# DSS_EDP0_COMMON_0_V2A_CORE_VP_REGS_APB register map
Vendor: Texas Instruments
Registers are 32-bit, access not given, reset 0x0 unless marked. A register's access mark holds for its fields unless they carry their own. Offsets are as the file gives them; [hi:lo] are bit positions; lines under a group give offsets from that group; {n}, {i} and the like mark numbered series; 'fields as' and 'values as' point back to an identical list.

## DSS_EDP0_COMMON_0_V2A_CORE_VP_REGS_APB (part 3 of 3)
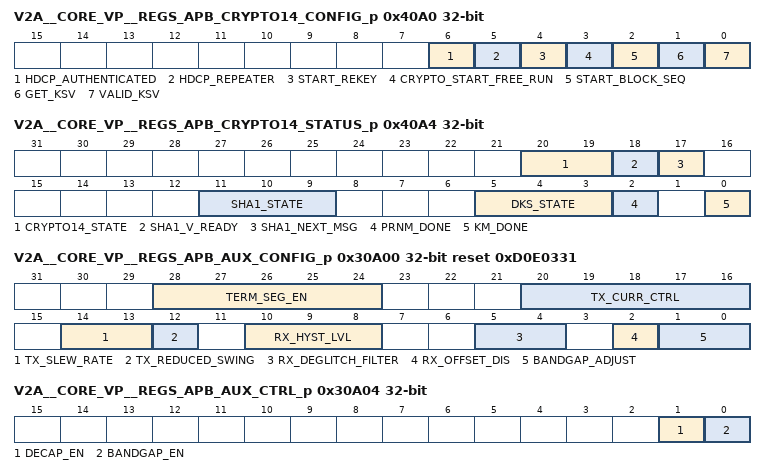
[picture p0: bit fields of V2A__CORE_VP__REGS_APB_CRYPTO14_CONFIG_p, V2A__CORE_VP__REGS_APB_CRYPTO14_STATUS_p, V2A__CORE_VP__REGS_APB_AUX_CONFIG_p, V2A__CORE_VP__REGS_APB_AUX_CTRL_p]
0x40A0 V2A__CORE_VP__REGS_APB_CRYPTO14_CONFIG_p
  [6] HDCP_AUTHENTICATED rw — Authenticated finished.
  [5] HDCP_REPEATER rw — Repeater bit : 0: for the receiver, 1: for the repeater
  [4] START_REKEY rw — Crypto 1.4 command to start hdcpRekeyCipher
  [3] CRYPTO_START_FREE_RUN rw — Crypto 1.4 command to start free running enable for operation hdcpRngCipher
  [2] START_BLOCK_SEQ rw — Crypto 1.4 command to start LFSR calculation
  [1] GET_KSV rw — Read it's own KSV enable bit.'0' reading not allowed'1' start reading.
  [0] VALID_KSV rw — Enable for Km calculation. When high, start calculating Km. Indicates a good moment for ri_out sampling.
0x40A4 V2A__CORE_VP__REGS_APB_CRYPTO14_STATUS_p
  [20:19] CRYPTO14_STATE ro — Crypto operation SM state: Possible values: 00- HDCP_RNG_CIPHER 01 - HDCP_BLOCK_CIPHER 10 - HDCP_STREAM_CIPHER 11 - HDCP_REKEY_CIPHER
  [18] SHA1_V_READY ro — Indication that V value from SHA-1 CRYPTO14_SHA1_V_VALUE_4 is ready.
  [17] SHA1_NEXT_MSG ro — Request for the next message block. When set high, CRYPTO14_SHA1_MSG_DATA_0-15 registers shall be written.
  [11:9] SHA1_STATE ro — Current state for Crypto 1.4 SHA-1 FSM. Used for debug purpose. Possible values: 000 - IDLE 001 - PREPARE 010 - CALCULATE 011 - RESULT 100 - BLOCK_WAIT
  [5:3] DKS_STATE ro — Crypto 1.4 DKS current state. Used for debug purpose. Possible values: 000 - HDCP_IDLE_KSV 010 - HDCP_IDLE 100 - HDCP_PRECALC 101 - HDCP_POSTCALC 110 - HDCP_CALC 111 - HDCP_READY
  [2] PRNM_DONE ro — LFSR and block output finished calculation.
  [0] KM_DONE ro — Done reading/calculating Km. Used as interrupt event.
0x40A8 V2A__CORE_VP__REGS_APB_CRYPTO14_PRNM_OUT_p
  [23:0] PRNM_OUT ro — 24-bit pseudo-random data.
0x40AC V2A__CORE_VP__REGS_APB_CRYPTO14_KM_0_p ro
  [31:0] CRYPTO14_KM_0 — Holds the first word of the Km value.
0x40B0 V2A__CORE_VP__REGS_APB_CRYPTO14_KM_1_p
  [23:0] CRYPTO14_KM_1 ro — Holds the most significant 3 bytes of the Km value.
0x40B4 V2A__CORE_VP__REGS_APB_CRYPTO14_AN_0_p rw
  [31:0] CRYPTO14_AN_0 — Holds the first 4 bytes of the An value.
0x40B8 V2A__CORE_VP__REGS_APB_CRYPTO14_AN_1_p rw
  [31:0] CRYPTO14_AN_1 — Holds the most significant 4 bytes of the An value.
0x40BC V2A__CORE_VP__REGS_APB_CRYPTO14_YOUR_KSV_0_p rw
  [31:0] CRYPTO14_YOUR_KSV_0 — Holds the first 32 bits of the KSV from the other HDCP device.
0x40C0 V2A__CORE_VP__REGS_APB_CRYPTO14_YOUR_KSV_1_p
  [7:0] CRYPTO14_YOUR_KSV_1 rw — Holds the last byte of the KSV from other HDCP device
0x40C4 V2A__CORE_VP__REGS_APB_CRYPTO14_MI_0_p ro
  [31:0] CRYPTO14_MI_0 — Mi value first 32 bits
0x40C8 V2A__CORE_VP__REGS_APB_CRYPTO14_MI_1_p ro
  [31:0] CRYPTO14_MI_1 — Mi value second 32 bits
0x40CC V2A__CORE_VP__REGS_APB_CRYPTO14_TI_0_p
  [15:0] CRYPTO14_TI_0 ro — Ti value
0x40D0 V2A__CORE_VP__REGS_APB_CRYPTO14_KI_0_p ro
  [31:0] CRYPTO14_KI_0 — Holds the first 32 bits of the Ki frame key from this HDCP device.
0x40D4 V2A__CORE_VP__REGS_APB_CRYPTO14_KI_1_p
  [23:0] CRYPTO14_KI_1 ro — Holds the last 3 bytes of the Ki frame key from this HDCP device.
0x40D8 V2A__CORE_VP__REGS_APB_CRYPTO14_BLOCKS_NUM_p rw
  [31:0] BLOCKS_NUM — Number of iterations for SHA-1 calculation.
0x40DC V2A__CORE_VP__REGS_APB_CRYPTO14_KEY_MEM_DATA_0_p rw
  [31:0] KEY_MEM_DATA_0 — Output data from keys RAM. Input for DKS block. First 32 bits.
0x40E0 V2A__CORE_VP__REGS_APB_CRYPTO14_KEY_MEM_DATA_1_p
  [23:0] KEY_MEM_DATA_1 rw — Output data from keys RAM. Input for DKS block. Last 3 bytes.
0x40E4 V2A__CORE_VP__REGS_APB_CRYPTO14_SHA1_MSG_DATA_p rw
  [31:0] SHA1_MSG_DATA — 32-bit word for SHA-1 message. Input for SHA-1 block.
0x40E8 V2A__CORE_VP__REGS_APB_CRYPTO14_SHA1_V_VALUE_0_p ro reset 0x67452301
  [31:0] V_VALUE_0 — First 32-bit word for SHA-1 calculation value. Output from SHA-1 block.
0x40EC V2A__CORE_VP__REGS_APB_CRYPTO14_SHA1_V_VALUE_1_p ro reset 0xEFCDAB89
  [31:0] V_VALUE_1 — Second 32-bit word for SHA-1 calculation value. Output from SHA-1 block.
0x40F0 V2A__CORE_VP__REGS_APB_CRYPTO14_SHA1_V_VALUE_2_p ro reset 0x98BADCFE
  [31:0] V_VALUE_2 — Third 32-bit word for SHA-1 calculation value. Output from SHA-1 block.
0x40F4 V2A__CORE_VP__REGS_APB_CRYPTO14_SHA1_V_VALUE_3_p ro reset 0x10325476
  [31:0] V_VALUE_3 — 4th 32-bit word for SHA-1 calculation value. Output from SHA-1 block.
0x40F8 V2A__CORE_VP__REGS_APB_CRYPTO14_SHA1_V_VALUE_4_p ro reset 0xC3D2E1F0
  [31:0] V_VALUE_4 — 5th 32-bit word for SHA-1 calculation value. Output from SHA-1 block.
0x10000 V2A__CORE_VP__REGS_APB_IRAM_REG_p rw
  [31:0] IRAM_DATA
0x20000 V2A__CORE_VP__REGS_APB_DRAM_REG_p rw
  [31:0] DRAM_DATA
0x30A00 V2A__CORE_VP__REGS_APB_AUX_CONFIG_p reset 0xD0E0331
  [28:24] TERM_SEG_EN rw — Enables output resistor segments for termination impedance.
  [20:16] TX_CURR_CTRL rw — TX current for output diff pair.
  [14:13] TX_SLEW_RATE rw — TX slew rate adjust.
  [12] TX_REDUCED_SWING rw — Control for lowering AUX transmitter swing level.
  [10:8] RX_HYST_LVL rw — Hysteresis control for AUX receiver front end.
  [5:4] RX_DEGLITCH_FILTER rw — Suppresses high-frequency pulses on AUX receiver output.
  [2] RX_OFFSET_DIS rw — Disables internal receiver cmn mode offset.
  [1:0] BANDGAP_ADJUST rw — Bandgap startup circuit adjust.
0x30A04 V2A__CORE_VP__REGS_APB_AUX_CTRL_p
  [1] DECAP_EN rw — Decap enable. Active HIGH. Asserted as long as DPTX system is enabled.
  [0] BANDGAP_EN rw — Bandgap enable. Active HIGH. Asserted when AUX channel needs to be used for request/response traffic - can be disabled after response is received if channel will not be needed for more than 4.5 microseconds.
0x30A08 V2A__CORE_VP__REGS_APB_AUX_ATBSEL_p
  [7:0] AUXIP_ATBSEL_ONEHOT rw
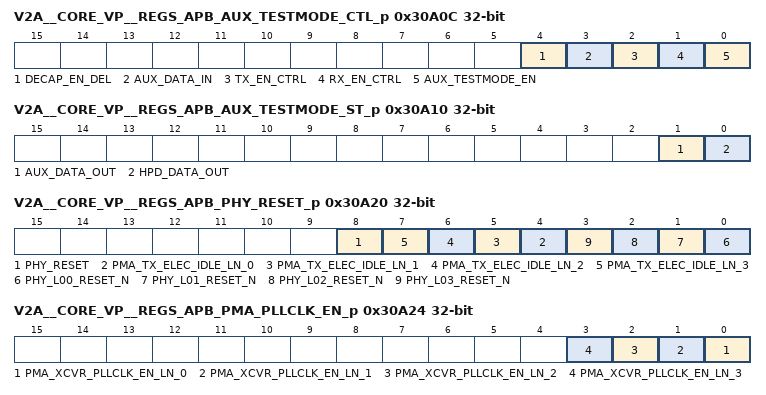
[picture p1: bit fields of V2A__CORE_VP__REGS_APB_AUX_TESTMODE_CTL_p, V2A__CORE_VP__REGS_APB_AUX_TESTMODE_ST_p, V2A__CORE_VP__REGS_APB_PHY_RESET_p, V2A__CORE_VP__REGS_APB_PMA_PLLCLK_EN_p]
0x30A0C V2A__CORE_VP__REGS_APB_AUX_TESTMODE_CTL_p
  [4] DECAP_EN_DEL rw — decap_en_del test value. Reflected at the decap_en_del output when aux_testmode_en=1
  [3] AUX_DATA_IN rw — aux_data_in test value. Reflected at the aux_data_in output when aux_testmode_en=1
  [2] TX_EN_CTRL rw — tx_en test value. Reflected at the tx_en output when aux_testmode_en=1
  [1] RX_EN_CTRL rw — rx_en test value. Reflected at the rx_en output when aux_testmode_en=1
  [0] AUX_TESTMODE_EN rw — AUX test enable. 0 - Test mode disabled 1 - test mode enabled, rx_en, tx_en, aux_data_in and decap_en_del are driven directly from the control rgisters
0x30A10 V2A__CORE_VP__REGS_APB_AUX_TESTMODE_ST_p
  [1] AUX_DATA_OUT ro — Raw status of aux_data_out output from AUX IP
  [0] HPD_DATA_OUT ro — Raw status of HPD output from AUX IP
0x30A20 V2A__CORE_VP__REGS_APB_PHY_RESET_p
  [8] PHY_RESET rw — 0 - reset all PHY logic for the entire PHY with the exception of the PHY APB registers, 1 - turn off reset. PHY reset is active LOW.
  [n+4] PMA_TX_ELEC_IDLE_LN_{n} rw (n=0..3) — PMA Tx electrical idle for line {n}. 1 - Tx differential output placed into electrical idle, 0 - transmit data.
  [n] PHY_L{n:02}_RESET_N rw (n=0..3) — 0 - turn on PHY l{n:02} reset with the exception of the PHY APB registers, 1 - turn off reset. PHY l{n:02} reset is active LOW.
0x30A24 V2A__CORE_VP__REGS_APB_PMA_PLLCLK_EN_p
  [n] PMA_XCVR_PLLCLK_EN_LN_{n} rw (n=0..3) — Link PLL clock enable used to cleanly turn off the data rate clock in the PMA for line {n}, 1 - enable Line {n} PLL clock. 0 - disable PLL clock.
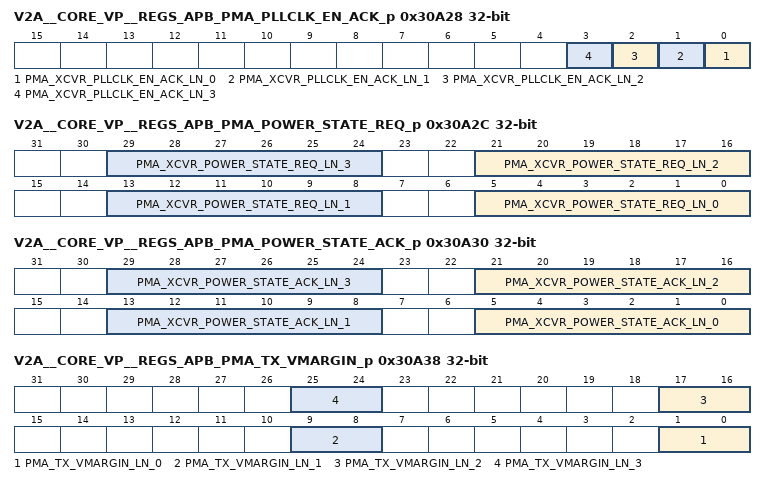
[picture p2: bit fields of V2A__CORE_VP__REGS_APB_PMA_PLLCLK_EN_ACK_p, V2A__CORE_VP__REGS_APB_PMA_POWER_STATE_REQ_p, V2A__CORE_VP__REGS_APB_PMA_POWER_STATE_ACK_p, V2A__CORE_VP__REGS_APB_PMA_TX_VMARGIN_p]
0x30A28 V2A__CORE_VP__REGS_APB_PMA_PLLCLK_EN_ACK_p
  [n] PMA_XCVR_PLLCLK_EN_ACK_LN_{n} ro (n=0..3) — Link PLL clock enable acknowledgement, indicates whether the data rate clock in the PMA for line {n} is running. Active HIGH.
0x30A2C V2A__CORE_VP__REGS_APB_PMA_POWER_STATE_REQ_p
  [8n+5:8n] PMA_XCVR_POWER_STATE_REQ_LN_{n} rw (n=0..3) — Change the link power state. When the link has completed the transition to the requested power state, the state will be reflected on pma_xcvr_power_state_ack_ln_{n}.
0x30A30 V2A__CORE_VP__REGS_APB_PMA_POWER_STATE_ACK_p
  [8n+5:8n] PMA_XCVR_POWER_STATE_ACK_LN_{n} ro (n=0..3) — Link power state acknowledgement, this signal provides indication that a power state change request has completed.
0x30A34 V2A__CORE_VP__REGS_APB_PMA_CMN_READY_p
  [0] PMA_CMN_READY ro — PMA common ready, 1 = PMA common is ready for operation. Used as part of Raw SerDes startup sequence and power state changes.
0x30A38 V2A__CORE_VP__REGS_APB_PMA_TX_VMARGIN_p
  [8n+1:8n] PMA_TX_VMARGIN_LN_{n} rw (n=0..3) — Drives PMA input tx_vmargin_ln_{n} for the associated lane. Drive with desired initial transit margin upon de-assertion of phy_reset_n.
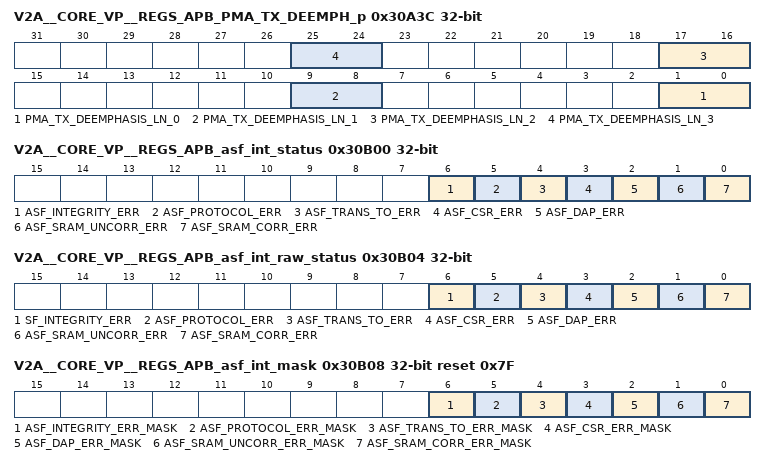
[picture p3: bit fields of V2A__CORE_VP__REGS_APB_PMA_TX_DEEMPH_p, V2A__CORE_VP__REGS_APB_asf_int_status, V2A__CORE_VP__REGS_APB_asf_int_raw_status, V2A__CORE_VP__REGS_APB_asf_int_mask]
0x30A3C V2A__CORE_VP__REGS_APB_PMA_TX_DEEMPH_p
  [8n+1:8n] PMA_TX_DEEMPHASIS_LN_{n} rw (n=0..3) — Drives PMA input tx_deemphasis_ln_{n} for the associated lane. Drives with desired initial deemphasis setting upon de-assertion of phy_reset_n.
0x30A60 V2A__CORE_VP__REGS_APB_asf_ips_ctrl reset 0x1
  [0] IF_ADDR_PARCHECK_EN rw — When set, enables parity check at APB/SAPB address bus. This bit should be enabled during normal operation but disabled in test mode when internal parity checkers are verified
0x30B00 V2A__CORE_VP__REGS_APB_asf_int_status
  [6] ASF_INTEGRITY_ERR rw — Integrity error interrupt,1 is active, 0 is not active
  [5] ASF_PROTOCOL_ERR rw — Protocol error interrupt,1 is active, 0 is not active
  [4] ASF_TRANS_TO_ERR rw — Transaction timeouts error interrupt,1 is active, 0 is not active
  [3] ASF_CSR_ERR rw — Configuration and status registers error interrupt,1 is active, 0 is not active
  [2] ASF_DAP_ERR rw — Data and address paths parity error interrupt,1 is active, 0 is not active
  [1] ASF_SRAM_UNCORR_ERR rw — SRAM uncorrectable error interrupt,1 is active, 0 is not active
  [0] ASF_SRAM_CORR_ERR rw — SRAM correctable error interrupt,1 is active, 0 is not active
0x30B04 V2A__CORE_VP__REGS_APB_asf_int_raw_status
  [6] SF_INTEGRITY_ERR rw — Integrity error interrupt,1 is active, 0 is not active
  [5] ASF_PROTOCOL_ERR rw — Protocol error interrupt,1 is active, 0 is not active
  [4] ASF_TRANS_TO_ERR rw — Transaction timeouts error interrupt,1 is active, 0 is not active
  [3] ASF_CSR_ERR rw — Configuration and status registers error interrupt,1 is active, 0 is not active
  [2] ASF_DAP_ERR rw — Data and address paths parity error interrupt,1 is active, 0 is not active
  [1] ASF_SRAM_UNCORR_ERR rw — SRAM uncorrectable error interrupt,1 is active, 0 is not active
  [0] ASF_SRAM_CORR_ERR rw — SRAM correctable error interrupt,1 is active, 0 is not active
0x30B08 V2A__CORE_VP__REGS_APB_asf_int_mask reset 0x7F
  [6] ASF_INTEGRITY_ERR_MASK rw — Mask bit for Integrity error interrupt, 0 is active, 1 is not active. Interrupt from source which mask is 0 is permitted, otherwise interrupt is not permitted
  [5] ASF_PROTOCOL_ERR_MASK rw — Mask bit for Protocol error interrupt, 0 is active, 1 is not active.Interrupt from source which mask is 0 is permitted, otherwise interrupt is not permitted
  [4] ASF_TRANS_TO_ERR_MASK rw — Mask bit for Transaction timeouts error interrupt, 0 is active, 1 is not active. Interrupt from source which mask is 0 is permitted, otherwise interrupt is not permitted
  [3] ASF_CSR_ERR_MASK rw — Mask bit for Configuration and status registers error interrupt, 0 is active, 1 is not active. Interrupt from source which mask is 0 is permitted, otherwise interrupt is not permitted
  [2] ASF_DAP_ERR_MASK rw — Mask bit for Data and address paths parity error interrupt, 0 is active, 1 is not active. Interrupt from source which mask is 0 is permitted, otherwise interrupt is not permitted
  [1] ASF_SRAM_UNCORR_ERR_MASK rw — Mask bit for SRAM uncorrectable error interrupt, 0 is active, 1 is not active. Interrupt from source which mask is 0 is permitted, otherwise interrupt is not permitted
  [0] ASF_SRAM_CORR_ERR_MASK rw — Mask bit for SRAM correctable error interrupt, 0 is active, 1 is not active. Interrupt from source which mask is 0 is permitted, otherwise interrupt is not permitted
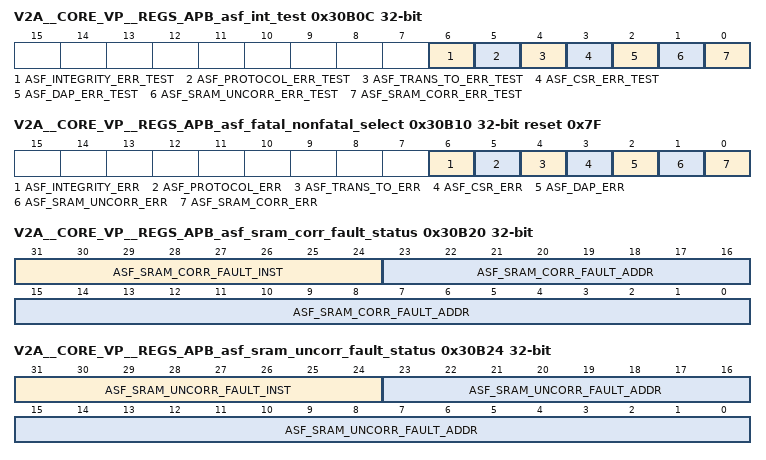
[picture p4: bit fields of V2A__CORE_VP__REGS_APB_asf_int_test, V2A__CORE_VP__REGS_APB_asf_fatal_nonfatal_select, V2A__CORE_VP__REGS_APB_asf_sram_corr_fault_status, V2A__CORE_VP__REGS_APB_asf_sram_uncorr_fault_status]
0x30B0C V2A__CORE_VP__REGS_APB_asf_int_test
  [6] ASF_INTEGRITY_ERR_TEST rw — Test bit for Integrity error interrupt,1 is active, 0 is not active
  [5] ASF_PROTOCOL_ERR_TEST rw — Test bit for Protocol error interrupt,1 is active, 0 is not active
  [4] ASF_TRANS_TO_ERR_TEST rw — Test bit for Transaction timeouts error interrupt,1 is active, 0 is not active
  [3] ASF_CSR_ERR_TEST rw — Test bit for Configuration and status registers error interrupt,1 is active, 0 is not active
  [2] ASF_DAP_ERR_TEST rw — Test bit for Data and address paths parity error interrupt,1 is active, 0 is not active
  [1] ASF_SRAM_UNCORR_ERR_TEST rw — Test bit for SRAM uncorrectable error interrupt,1 is active, 0 is not active
  [0] ASF_SRAM_CORR_ERR_TEST rw — Test bit for SRAM correctable error interrupt,1 is active, 0 is not active
0x30B10 V2A__CORE_VP__REGS_APB_asf_fatal_nonfatal_select reset 0x7F
  [6] ASF_INTEGRITY_ERR rw — Enable Integrity error interrupt as fatal,1 is fatal interrupt, 0 is non-fatal
  [5] ASF_PROTOCOL_ERR rw — Enable Protocol error interrupt as fatal,1 is fatal interrupt, 0 is non-fatal
  [4] ASF_TRANS_TO_ERR rw — Enable Transaction timeouts error interrupt as fatal,1 is fatal interrupt, 0 is non-fatal
  [3] ASF_CSR_ERR rw — Enable Configuration and status registers error interrupt as fatal,1 is fatal interrupt, 0 is non-fatal
  [2] ASF_DAP_ERR rw — Enable Data and address paths parity error interrupt as fatal,1 is fatal interrupt, 0 is non-fatal
  [1] ASF_SRAM_UNCORR_ERR rw — Enable SRAM uncorrectable error interrupt as fatal,1 is fatal interrupt, 0 is non-fatal
  [0] ASF_SRAM_CORR_ERR rw — Enable SRAM correctable error interrupt as fatal,1 is fatal interrupt, 0 is non-fatal
0x30B20 V2A__CORE_VP__REGS_APB_asf_sram_corr_fault_status ro
  [31:24] ASF_SRAM_CORR_FAULT_INST — Last SRAM instance that generated fault
  [23:0] ASF_SRAM_CORR_FAULT_ADDR — Last SRAM address that generated fault
0x30B24 V2A__CORE_VP__REGS_APB_asf_sram_uncorr_fault_status ro
  [31:24] ASF_SRAM_UNCORR_FAULT_INST — Last SRAM instance that generated fault
  [23:0] ASF_SRAM_UNCORR_FAULT_ADDR — Last SRAM address that generated fault
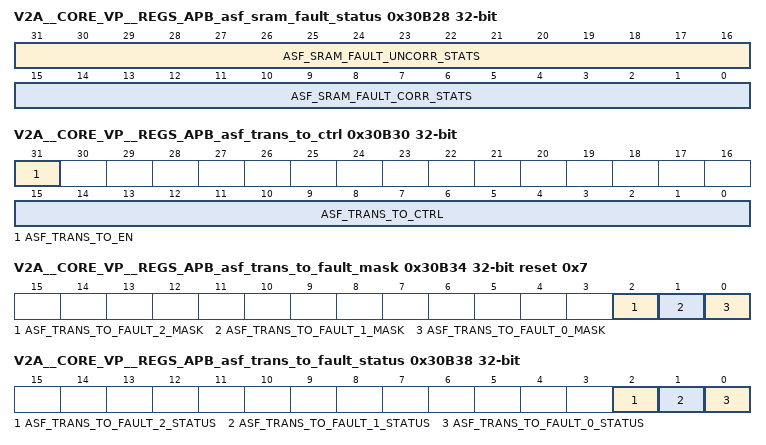
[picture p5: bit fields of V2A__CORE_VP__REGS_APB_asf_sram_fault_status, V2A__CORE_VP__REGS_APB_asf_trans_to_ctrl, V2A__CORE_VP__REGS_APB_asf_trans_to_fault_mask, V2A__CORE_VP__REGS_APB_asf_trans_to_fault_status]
0x30B28 V2A__CORE_VP__REGS_APB_asf_sram_fault_status rw
  [31:16] ASF_SRAM_FAULT_UNCORR_STATS — Count of number of uncorrectable errors if implemented. Count value will saturate at 0xffff
  [15:0] ASF_SRAM_FAULT_CORR_STATS — Count of number of correctable errors if implemented. Count value will saturate at 0xffff
0x30B30 V2A__CORE_VP__REGS_APB_asf_trans_to_ctrl
  [31] ASF_TRANS_TO_EN rw — Enable transaction timeout monitoring,1 is active,0 is not active
  [15:0] ASF_TRANS_TO_CTRL rw — Timer value to use for transaction timeout monitor
0x30B34 V2A__CORE_VP__REGS_APB_asf_trans_to_fault_mask reset 0x7
  [2] ASF_TRANS_TO_FAULT_2_MASK rw — Mask bit for SAPB interface for transaction timeout fault,0 is active, 1 is not active.Interrupt from source which mask is 0 is permitted, otherwise interrupt is not permitted
  [1] ASF_TRANS_TO_FAULT_1_MASK rw — Mask bit for APB interface for transaction timeout fault,0 is active, 1 is not active.Interrupt from source which mask is 0 is permitted, otherwise interrupt is not permitted
  [0] ASF_TRANS_TO_FAULT_0_MASK rw — Mask bit for Xtensa watchdog error for transaction timeout fault,0 is active, 1 is not active.Interrupt from source which mask is 0 is permitted, otherwise interrupt is not permitted
0x30B38 V2A__CORE_VP__REGS_APB_asf_trans_to_fault_status
  [2] ASF_TRANS_TO_FAULT_2_STATUS rw — Status bits for SAPB interface for transaction timeout fault,1 is active, 0 is not active
  [1] ASF_TRANS_TO_FAULT_1_STATUS rw — Status bits for APB interface for transaction timeout fault,1 is active, 0 is not active
  [0] ASF_TRANS_TO_FAULT_0_STATUS rw — Status bits for Xtensa watchdog error for transaction timeout fault,1 is active, 0 is not active
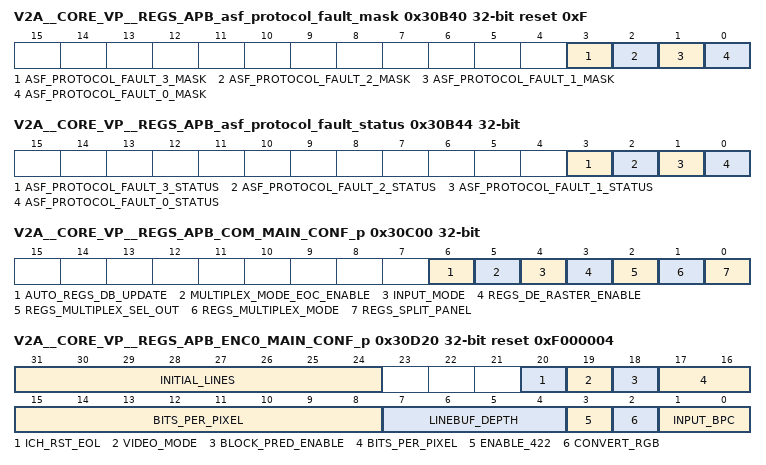
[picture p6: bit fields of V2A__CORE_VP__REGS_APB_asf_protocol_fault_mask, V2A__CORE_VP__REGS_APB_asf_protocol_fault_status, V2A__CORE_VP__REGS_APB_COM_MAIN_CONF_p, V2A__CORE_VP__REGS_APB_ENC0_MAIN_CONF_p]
0x30B40 V2A__CORE_VP__REGS_APB_asf_protocol_fault_mask reset 0xF
  [3] ASF_PROTOCOL_FAULT_3_MASK rw — Mask bit for FEC FSM fault. When 0 interrupt is enabled.
  [2] ASF_PROTOCOL_FAULT_2_MASK rw — Mask bit for 8b10b Encoding fault from FEC module. When 0 interrupt is enabled.
  [1] ASF_PROTOCOL_FAULT_1_MASK rw — Mask bit for Party Encoding fault from FEC module. When 0 interrupt is enabled.
  [0] ASF_PROTOCOL_FAULT_0_MASK rw — Mask bit for Parity Generation fault from FEC module. When 0 interrupt is enabled.
0x30B44 V2A__CORE_VP__REGS_APB_asf_protocol_fault_status
  [3] ASF_PROTOCOL_FAULT_3_STATUS rw — FEC symbol injection fault. Active HIGH. Asserten when FEC FSM is in unexpected state.
  [2] ASF_PROTOCOL_FAULT_2_STATUS rw — 8b10b Encoding fault in FEC module. Active HIGH. Asserted when fault in 8b10b encoding is detected.
  [1] ASF_PROTOCOL_FAULT_1_STATUS rw — Party Encoding fault in FEC module. Active HIGH. Asserted when fault in RS parity encoding is detected.
  [0] ASF_PROTOCOL_FAULT_0_STATUS rw — Parity Generation fault in FEC module. Active HIGH. Asserted when fault in RS parity generation is detected.
0x30C00 V2A__CORE_VP__REGS_APB_COM_MAIN_CONF_p
  [6] AUTO_REGS_DB_UPDATE rw — Active-High to enable auto update double buffer regs on vsync falling edge. Only available when input_mode=1 [DPI mode]
  [5] MULTIPLEX_MODE_EOC_ENABLE rw — When split_panel and multiplex_mode are set, indicates that multiplexer output separated chunks [inserts zeros on partial words at each end of chunk] and signal end of chunks. Active high
  [4] INPUT_MODE rw — Video input interface mode: 0: Native 1: DPI. Input mode set to DPI automatically enable the internal Auto Start Of Frame
  [3] REGS_DE_RASTER_ENABLE rw — Indicates if the De-Rasterization Buffer is used or bypassed: '1' Active '0' Bypassed
  [2] REGS_MULTIPLEX_SEL_OUT rw — When split_panel and multiplex_mode are set, indicates to which output the multiplexed stream is sent: '0': enc0_data_out '1': enc1_data_out
  [1] REGS_MULTIPLEX_MODE rw — Active-High, indicates that both encoders are used to produce a multiplex stream on a single Transport link. When set, split_panel must also be set.
  [0] REGS_SPLIT_PANEL rw — Active-High, indicates that both encoders are used in parallel for one video stream [L and R split]. When set, the effective width of each encoder is halved [as each encoder is operating on half of the encx_picture_width]. In addition, the ICH is cleared at the end of each line.
0x30D20 V2A__CORE_VP__REGS_APB_ENC0_MAIN_CONF_p reset 0xF000004
  [31:24] INITIAL_LINES rw — Number of lines to wait before initiating transport in Command Mode.
  [20] ICH_RST_EOL rw — Forces the ICH to reset at EOL [when not in split mode].
  [19] VIDEO_MODE rw — MIPI Video/Command mode: '0' Command mode '1' Video mode
  [18] BLOCK_PRED_ENABLE rw — Active-High input Block Prediction Enable
  [17:8] BITS_PER_PIXEL rw — Target bits per pixel. The value is in 6.4 format [4 LSBs for fractional part, they should be 0000]
  [7:4] LINEBUF_DEPTH rw — Depth of the line buffer used by the decoder [i.e., the number of bits stored for each component of the pixels on the previous line]
  [3] ENABLE_422 rw — Active-High input to indicate the data_in pixels are 4:2:2 sub-sampled. This input is valid only when convert_rgb is low. NOT SUPPORTED, MUST BE SET TO '0'
  [2] CONVERT_RGB rw — Active-High input to indicate the data_in pixels are RGB. When set to low input, it is YUV and does not require conversion.
  [1:0] INPUT_BPC rw — Indicates the current input pixel stream bits per component: 00: input is 8 bits/component 01: input is 10 bits/component
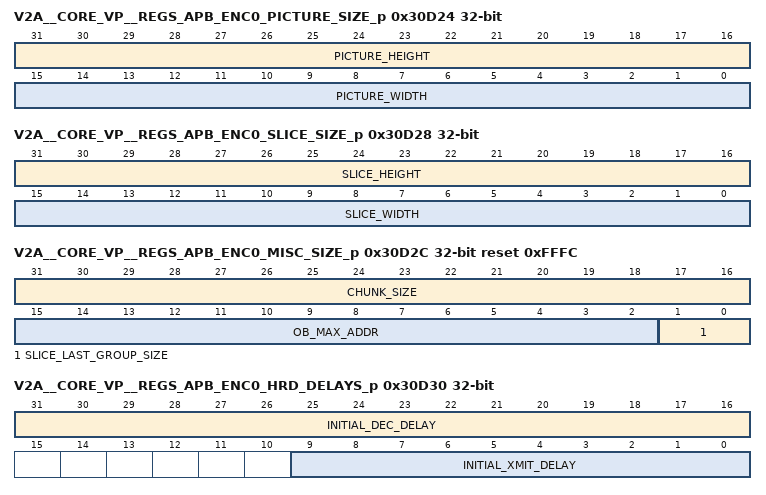
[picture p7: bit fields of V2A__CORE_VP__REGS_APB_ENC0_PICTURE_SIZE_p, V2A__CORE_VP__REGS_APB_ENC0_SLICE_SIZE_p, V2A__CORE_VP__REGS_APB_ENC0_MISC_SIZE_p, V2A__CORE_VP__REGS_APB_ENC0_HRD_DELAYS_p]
0x30D24 V2A__CORE_VP__REGS_APB_ENC0_PICTURE_SIZE_p rw
  [31:16] PICTURE_HEIGHT, [15:0] PICTURE_WIDTH
0x30D28 V2A__CORE_VP__REGS_APB_ENC0_SLICE_SIZE_p rw
  [31:16] SLICE_HEIGHT, [15:0] SLICE_WIDTH
0x30D2C V2A__CORE_VP__REGS_APB_ENC0_MISC_SIZE_p rw reset 0xFFFC
  [31:16] CHUNK_SIZE — Chunk size in bytes
  [15:2] OB_MAX_ADDR — Output Buffer[s] max pointer address[es]
  [1:0] SLICE_LAST_GROUP_SIZE — Size of last group of the slice line [0-based]: 0 = 1 pixel, 1 = 2 pixels, 2 = 3 pixels [slice_width + 2] % 3
0x30D30 V2A__CORE_VP__REGS_APB_ENC0_HRD_DELAYS_p
  [31:16] INITIAL_DEC_DELAY rw — Initial Decoder delay
  [9:0] INITIAL_XMIT_DELAY rw — Initial Decoder Transmit delay
0x30D34 V2A__CORE_VP__REGS_APB_ENC0_RC_SCALE_p
  [5:0] INITIAL_SCALE_VALUE rw — Three fractional bits
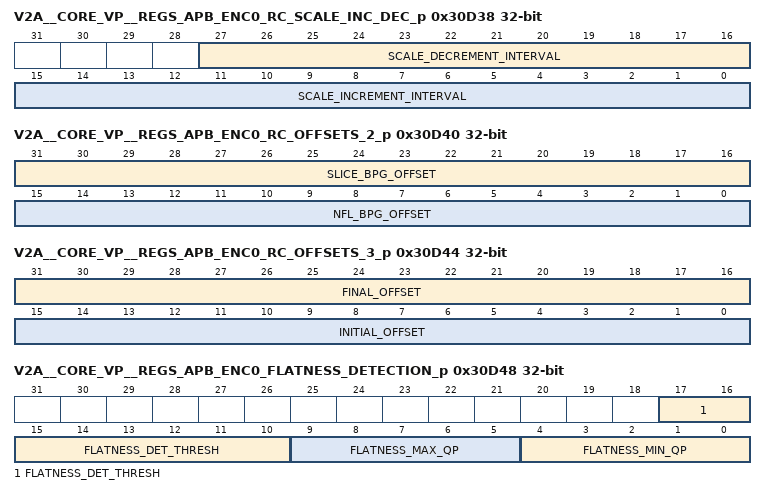
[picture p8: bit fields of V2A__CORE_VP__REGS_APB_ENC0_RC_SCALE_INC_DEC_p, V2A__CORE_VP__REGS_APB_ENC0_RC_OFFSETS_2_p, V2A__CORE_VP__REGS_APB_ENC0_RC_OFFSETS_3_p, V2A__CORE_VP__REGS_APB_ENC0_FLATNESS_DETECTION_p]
0x30D38 V2A__CORE_VP__REGS_APB_ENC0_RC_SCALE_INC_DEC_p
  [27:16] SCALE_DECREMENT_INTERVAL rw — RC scale decrement value
  [15:0] SCALE_INCREMENT_INTERVAL rw — RC scale increment value
0x30D3C V2A__CORE_VP__REGS_APB_ENC0_RC_OFFSETS_1_p
  [4:0] FIRST_LINE_BPG_OFFSET rw — First Line
0x30D40 V2A__CORE_VP__REGS_APB_ENC0_RC_OFFSETS_2_p rw
  [31:16] SLICE_BPG_OFFSET — Extra budget per group [11 fractional bits]
  [15:0] NFL_BPG_OFFSET — Non First Line [11 fractional bits]
0x30D44 V2A__CORE_VP__REGS_APB_ENC0_RC_OFFSETS_3_p rw
  [31:16] FINAL_OFFSET, [15:0] INITIAL_OFFSET
0x30D48 V2A__CORE_VP__REGS_APB_ENC0_FLATNESS_DETECTION_p
  [17:10] FLATNESS_DET_THRESH rw — Flatness Detection Threshold, as defined in PPS table of the DSC specification
  [9:5] FLATNESS_MAX_QP rw — Maximum threshold
  [4:0] FLATNESS_MIN_QP rw — Minimum threshold
0x30D4C V2A__CORE_VP__REGS_APB_ENC0_RC_MODEL_SIZE_p
  [15:0] RC_MODEL_SIZE rw
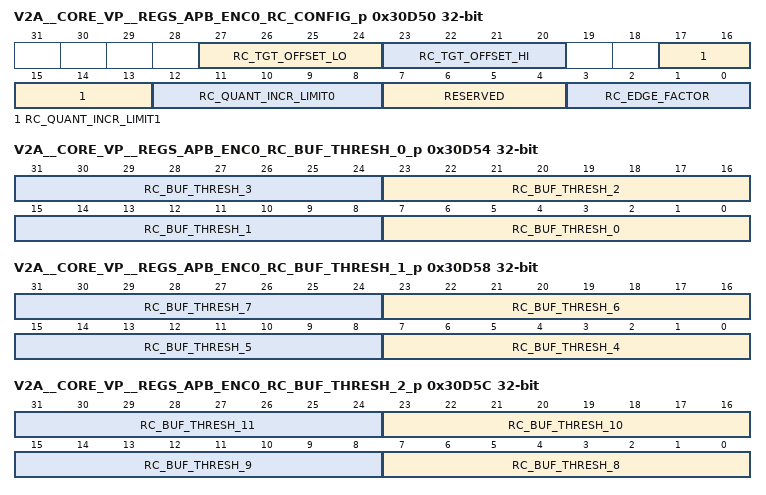
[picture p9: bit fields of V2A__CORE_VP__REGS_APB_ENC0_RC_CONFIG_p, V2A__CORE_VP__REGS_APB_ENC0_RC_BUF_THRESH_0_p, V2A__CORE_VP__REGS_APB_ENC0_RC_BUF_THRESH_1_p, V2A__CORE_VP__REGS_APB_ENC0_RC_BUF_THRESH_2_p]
0x30D50 V2A__CORE_VP__REGS_APB_ENC0_RC_CONFIG_p
  [27:24] RC_TGT_OFFSET_LO rw — RC Target offset low
  [23:20] RC_TGT_OFFSET_HI rw — RC Target offset high
  [17:13] RC_QUANT_INCR_LIMIT1 rw — RC quantization increment limit 1
  [12:8] RC_QUANT_INCR_LIMIT0 rw — RC quantization increment limit 0
  [7:4] RESERVED — RC Edge factor [1 fractional bit] (access N/A)
  [3:0] RC_EDGE_FACTOR rw — Reserved. Writes are ignored. 0x0 when read
0x30D54 V2A__CORE_VP__REGS_APB_ENC0_RC_BUF_THRESH_0_p rw
  [8n+7:8n] RC_BUF_THRESH_{n} (n=0..3) — 8 MSBs of the value. Values in configuration files are 14 bits but 6 LSBs are always 0
0x30D58 V2A__CORE_VP__REGS_APB_ENC0_RC_BUF_THRESH_1_p rw
  [8n-25:8n-32] RC_BUF_THRESH_{n} (n=4..7) — 8 MSBs of the value. Values in configuration files are 14 bits but 6 LSBs are always 0
0x30D5C V2A__CORE_VP__REGS_APB_ENC0_RC_BUF_THRESH_2_p rw
  [8n-57:8n-64] RC_BUF_THRESH_{n} (n=8..11) — 8 MSBs of the value. Values in configuration files are 14 bits but 6 LSBs are always 0
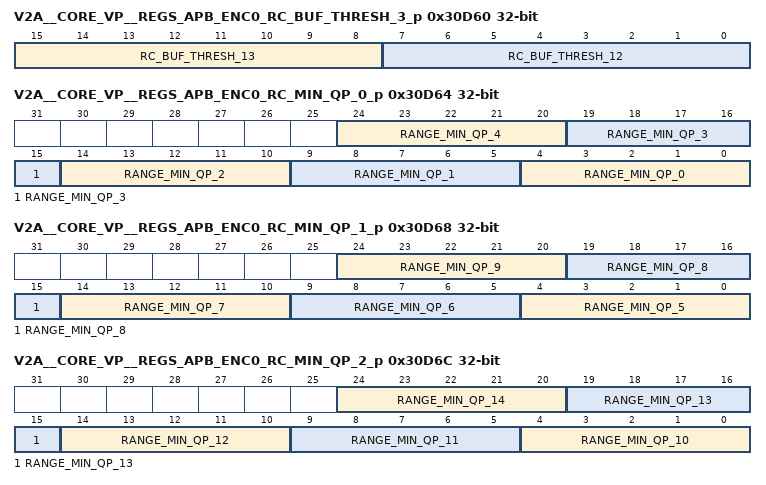
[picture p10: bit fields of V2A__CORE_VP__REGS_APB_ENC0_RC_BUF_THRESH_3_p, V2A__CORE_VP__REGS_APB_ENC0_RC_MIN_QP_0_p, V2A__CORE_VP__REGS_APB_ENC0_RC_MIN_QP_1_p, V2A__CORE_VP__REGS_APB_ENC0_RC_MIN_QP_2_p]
0x30D60 V2A__CORE_VP__REGS_APB_ENC0_RC_BUF_THRESH_3_p
  [15:8] RC_BUF_THRESH_13 rw — 8 MSBs of the value. Values in configuration files are 14 bits but 6 LSBs are always 0
  [7:0] RC_BUF_THRESH_12 rw — 8 MSBs of the value. Values in configuration files are 14 bits but 6 LSBs are always 0
0x30D64 V2A__CORE_VP__REGS_APB_ENC0_RC_MIN_QP_0_p
  [5n+4:5n] RANGE_MIN_QP_{n} rw (n=0..4) — As per DSC specification
0x30D68 V2A__CORE_VP__REGS_APB_ENC0_RC_MIN_QP_1_p
  [5n-21:5n-25] RANGE_MIN_QP_{n} rw (n=5..9) — As per DSC specification
0x30D6C V2A__CORE_VP__REGS_APB_ENC0_RC_MIN_QP_2_p
  [5n-46:5n-50] RANGE_MIN_QP_{n} rw (n=10..14) — As per DSC specification
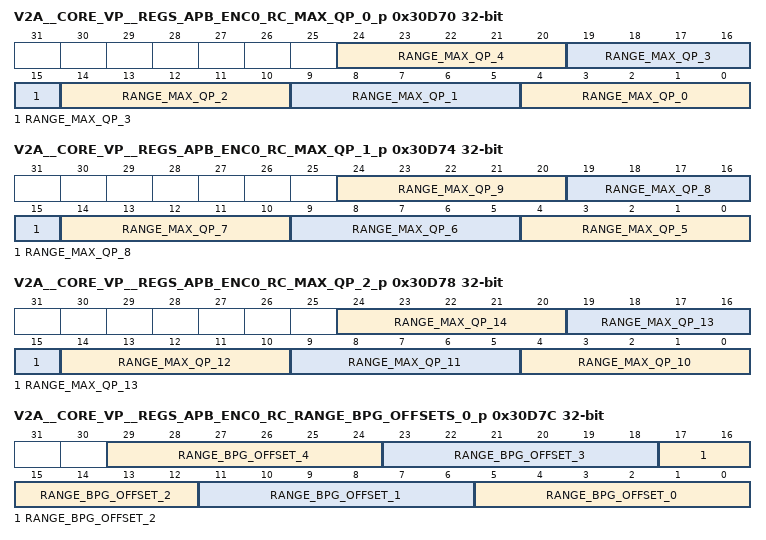
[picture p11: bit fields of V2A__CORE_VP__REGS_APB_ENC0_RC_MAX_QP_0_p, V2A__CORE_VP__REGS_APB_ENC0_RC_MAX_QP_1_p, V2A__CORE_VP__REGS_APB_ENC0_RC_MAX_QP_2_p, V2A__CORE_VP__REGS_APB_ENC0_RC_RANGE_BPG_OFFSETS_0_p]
0x30D70 V2A__CORE_VP__REGS_APB_ENC0_RC_MAX_QP_0_p
  [5n+4:5n] RANGE_MAX_QP_{n} rw (n=0..4) — As per DSC specification
0x30D74 V2A__CORE_VP__REGS_APB_ENC0_RC_MAX_QP_1_p
  [5n-21:5n-25] RANGE_MAX_QP_{n} rw (n=5..9) — As per DSC specification
0x30D78 V2A__CORE_VP__REGS_APB_ENC0_RC_MAX_QP_2_p
  [5n-46:5n-50] RANGE_MAX_QP_{n} rw (n=10..14) — As per DSC specification
0x30D7C V2A__CORE_VP__REGS_APB_ENC0_RC_RANGE_BPG_OFFSETS_0_p
  [6n+5:6n] RANGE_BPG_OFFSET_{n} rw (n=0..4) — As per DSC specification
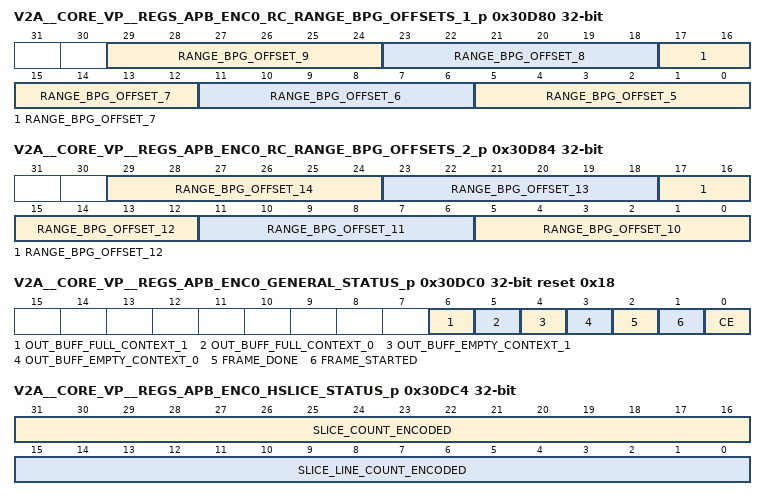
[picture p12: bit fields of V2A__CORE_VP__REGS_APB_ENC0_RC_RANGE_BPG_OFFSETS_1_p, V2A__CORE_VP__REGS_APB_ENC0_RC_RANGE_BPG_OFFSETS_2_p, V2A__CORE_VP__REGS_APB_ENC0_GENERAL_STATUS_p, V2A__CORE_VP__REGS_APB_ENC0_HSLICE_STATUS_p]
0x30D80 V2A__CORE_VP__REGS_APB_ENC0_RC_RANGE_BPG_OFFSETS_1_p
  [6n-25:6n-30] RANGE_BPG_OFFSET_{n} rw (n=5..9) — As per DSC specification
0x30D84 V2A__CORE_VP__REGS_APB_ENC0_RC_RANGE_BPG_OFFSETS_2_p
  [6n-55:6n-60] RANGE_BPG_OFFSET_{n} rw (n=10..14) — As per DSC specification
0x30D88 V2A__CORE_VP__REGS_APB_ENC0_DPI_CTRL_OUT_DELAY_p
  [15:0] DPI_CTRL_OUT_DELAY rw — Delay in number of encx clock cycles. The delay should equal to InitialLines x Htotal[clk] where Htotal is the upstream source timing controller total line time [in clock cycles, not in pixels] including the horizontal blanking [Htotal[clk] = Hactive[clk] + Hblank[clk]]When in split panel mode, the Hactive[clk] is expected to be picture_width divided by 2
0x30DC0 V2A__CORE_VP__REGS_APB_ENC0_GENERAL_STATUS_p reset 0x18
  [6] OUT_BUFF_FULL_CONTEXT_1 ro — Output buffer 1 [soft slice 1] is full.For Debug purposes only.
  [5] OUT_BUFF_FULL_CONTEXT_0 ro — Output buffer 0 [soft slice 0] is full.For Debug purposes only.
  [4] OUT_BUFF_EMPTY_CONTEXT_1 ro — Output buffer 1 [soft slice 1] is empty.For Debug purposes only.
  [3] OUT_BUFF_EMPTY_CONTEXT_0 ro — Output buffer 0 [soft slice 0] is empty.For Debug purposes only.
  [2] FRAME_DONE ro — Encoder finished a frame
  [1] FRAME_STARTED ro — Encoder is currently processing a frame
  [0] CE ro — Flow control internal clock enable status.For Debug purposes only.
0x30DC4 V2A__CORE_VP__REGS_APB_ENC0_HSLICE_STATUS_p ro
  [31:16] SLICE_COUNT_ENCODED — Actual slice number of current frame being processed at VLC encoder.Not re-synchronized in register clock domain. For Debug purposes only.
  [15:0] SLICE_LINE_COUNT_ENCODED — Actual line number of current slice being processed at VLC encoder.Not re-synchronized in register clock domain. For Debug purposes only.
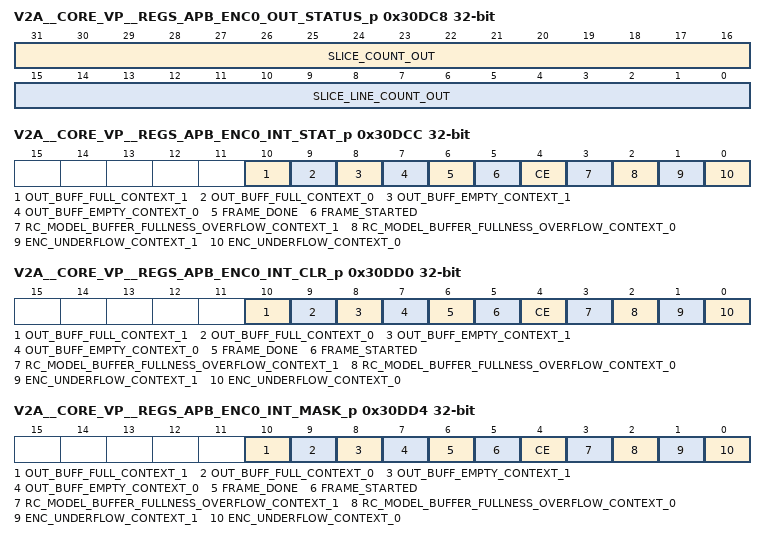
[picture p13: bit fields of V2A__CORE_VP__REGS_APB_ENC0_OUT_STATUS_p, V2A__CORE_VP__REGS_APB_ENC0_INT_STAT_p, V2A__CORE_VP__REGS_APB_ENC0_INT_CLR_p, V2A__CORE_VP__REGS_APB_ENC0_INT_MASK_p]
0x30DC8 V2A__CORE_VP__REGS_APB_ENC0_OUT_STATUS_p ro
  [31:16] SLICE_COUNT_OUT — Actual slice number of current frame being read at output interface.Not re-synchronized in register clock domain. For Debug purposes only.
  [15:0] SLICE_LINE_COUNT_OUT — Actual line number of current slice being read at output interface.Not re-synchronized in register clock domain. For Debug purposes only.
0x30DCC V2A__CORE_VP__REGS_APB_ENC0_INT_STAT_p
  [10] OUT_BUFF_FULL_CONTEXT_1 ro — Output buffer 1 [soft slice 1] became full
  [9] OUT_BUFF_FULL_CONTEXT_0 ro — Output buffer 0 [soft slice 0] became full
  [8] OUT_BUFF_EMPTY_CONTEXT_1 ro — Output buffer 1 [soft slice 1] became empty
  [7] OUT_BUFF_EMPTY_CONTEXT_0 ro — Output buffer 0 [soft slice 0] became empty
  [6] FRAME_DONE ro — Encoder finished a frame
  [5] FRAME_STARTED ro — Encoder is started to process a frame
  [4] CE ro — Flow control internal clock enable becomes high
  [3] RC_MODEL_BUFFER_FULLNESS_OVERFLOW_CONTEXT_1 ro — rc_model_buffer 1 [soft slice 1] overflow
  [2] RC_MODEL_BUFFER_FULLNESS_OVERFLOW_CONTEXT_0 ro — rc_model_buffer 0 [soft slice 0] overflow
  [1] ENC_UNDERFLOW_CONTEXT_1 ro — output buffer 1 [soft slice 1] underflow
  [0] ENC_UNDERFLOW_CONTEXT_0 ro — output buffer 0 [soft slice 0] underflow
0x30DD0 V2A__CORE_VP__REGS_APB_ENC0_INT_CLR_p
  [10] OUT_BUFF_FULL_CONTEXT_1 rw — Output buffer 1 [soft slice 1] became full
  [9] OUT_BUFF_FULL_CONTEXT_0 rw — Output buffer 0 [soft slice 0] became full
  [8] OUT_BUFF_EMPTY_CONTEXT_1 rw — Output buffer 1 [soft slice 1] became empty
  [7] OUT_BUFF_EMPTY_CONTEXT_0 rw — Output buffer 0 [soft slice 0] became empty
  [6] FRAME_DONE rw — Encoder finished a frame
  [5] FRAME_STARTED rw — Encoder is started to process a frame
  [4] CE rw — Flow control internal clock enable
  [3] RC_MODEL_BUFFER_FULLNESS_OVERFLOW_CONTEXT_1 rw — rc model buffer 1 overflow
  [2] RC_MODEL_BUFFER_FULLNESS_OVERFLOW_CONTEXT_0 rw — rc model buffer 0 overflow
  [1] ENC_UNDERFLOW_CONTEXT_1 rw — output buffer 1 underflow
  [0] ENC_UNDERFLOW_CONTEXT_0 rw — output buffer 0 underflow
0x30DD4 V2A__CORE_VP__REGS_APB_ENC0_INT_MASK_p
  [10] OUT_BUFF_FULL_CONTEXT_1 rw — Output buffer 1 [soft slice 1] became full
  [9] OUT_BUFF_FULL_CONTEXT_0 rw — Output buffer 0 [soft slice 0] became full
  [8] OUT_BUFF_EMPTY_CONTEXT_1 rw — Output buffer 1 [soft slice 1] became empty
  [7] OUT_BUFF_EMPTY_CONTEXT_0 rw — Output buffer 0 [soft slice 0] became empty
  [6] FRAME_DONE rw — Encoder finished a frame
  [5] FRAME_STARTED rw — Encoder is started to process a frame
  [4] CE rw — Flow control internal clock enable
  [3] RC_MODEL_BUFFER_FULLNESS_OVERFLOW_CONTEXT_1 rw — rc model buffer 1 overflow
  [2] RC_MODEL_BUFFER_FULLNESS_OVERFLOW_CONTEXT_0 rw — rc model buffer 0 overflow
  [1] ENC_UNDERFLOW_CONTEXT_1 rw — enc underflow 1 underflow
  [0] ENC_UNDERFLOW_CONTEXT_0 rw — enc underflow 0 underflow
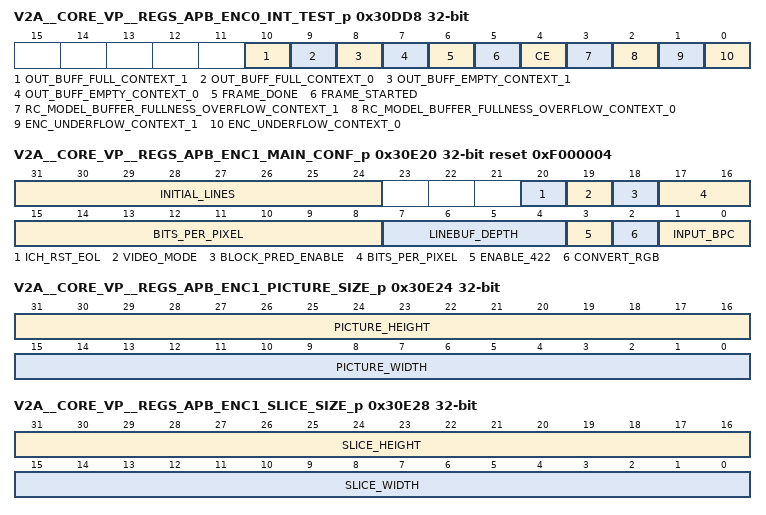
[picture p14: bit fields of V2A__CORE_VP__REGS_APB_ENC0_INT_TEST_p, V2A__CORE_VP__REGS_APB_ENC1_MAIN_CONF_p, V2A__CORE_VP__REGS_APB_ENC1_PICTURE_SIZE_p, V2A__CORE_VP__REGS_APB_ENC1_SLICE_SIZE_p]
0x30DD8 V2A__CORE_VP__REGS_APB_ENC0_INT_TEST_p
  [10] OUT_BUFF_FULL_CONTEXT_1 rw — Output buffer 1 [soft slice 1] became full test
  [9] OUT_BUFF_FULL_CONTEXT_0 rw — Output buffer 0 [soft slice 0] became full test
  [8] OUT_BUFF_EMPTY_CONTEXT_1 rw — Output buffer 1 [soft slice 1] became empty test
  [7] OUT_BUFF_EMPTY_CONTEXT_0 rw — Output buffer 0 [soft slice 0] became empty test
  [6] FRAME_DONE rw — Encoder finished a frame test
  [5] FRAME_STARTED rw — Encoder is started to process a frame test
  [4] CE rw — Flow control internal clock enable test
  [3] RC_MODEL_BUFFER_FULLNESS_OVERFLOW_CONTEXT_1 rw — rc model buffer 1 overflow test
  [2] RC_MODEL_BUFFER_FULLNESS_OVERFLOW_CONTEXT_0 rw — rc model buffer 0 overflow test
  [1] ENC_UNDERFLOW_CONTEXT_1 rw — enc underflow 1 underflow test
  [0] ENC_UNDERFLOW_CONTEXT_0 rw — enc underflow 0 underflow test
0x30E20 V2A__CORE_VP__REGS_APB_ENC1_MAIN_CONF_p reset 0xF000004
  fields as V2A__CORE_VP__REGS_APB_ENC0_MAIN_CONF_p
0x30E24 V2A__CORE_VP__REGS_APB_ENC1_PICTURE_SIZE_p rw
  [31:16] PICTURE_HEIGHT, [15:0] PICTURE_WIDTH
0x30E28 V2A__CORE_VP__REGS_APB_ENC1_SLICE_SIZE_p rw
  [31:16] SLICE_HEIGHT, [15:0] SLICE_WIDTH
0x30E2C V2A__CORE_VP__REGS_APB_ENC1_MISC_SIZE_p rw reset 0xFFFC
  fields as V2A__CORE_VP__REGS_APB_ENC0_MISC_SIZE_p
0x30E30 V2A__CORE_VP__REGS_APB_ENC1_HRD_DELAYS_p
  fields as V2A__CORE_VP__REGS_APB_ENC0_HRD_DELAYS_p
0x30E34 V2A__CORE_VP__REGS_APB_ENC1_RC_SCALE_p
  [5:0] INITIAL_SCALE_VALUE rw — Three fractional bits
0x30E38 V2A__CORE_VP__REGS_APB_ENC1_RC_SCALE_INC_DEC_p
  fields as V2A__CORE_VP__REGS_APB_ENC0_RC_SCALE_INC_DEC_p
0x30E3C V2A__CORE_VP__REGS_APB_ENC1_RC_OFFSETS_1_p
  [4:0] FIRST_LINE_BPG_OFFSET rw — First Line
0x30E40 V2A__CORE_VP__REGS_APB_ENC1_RC_OFFSETS_2_p rw
  fields as V2A__CORE_VP__REGS_APB_ENC0_RC_OFFSETS_2_p
0x30E44 V2A__CORE_VP__REGS_APB_ENC1_RC_OFFSETS_3_p rw
  [31:16] FINAL_OFFSET, [15:0] INITIAL_OFFSET
0x30E48 V2A__CORE_VP__REGS_APB_ENC1_FLATNESS_DETECTION_p
  fields as V2A__CORE_VP__REGS_APB_ENC0_FLATNESS_DETECTION_p
0x30E4C V2A__CORE_VP__REGS_APB_ENC1_RC_MODEL_SIZE_p
  [15:0] RC_MODEL_SIZE rw
0x30E50 V2A__CORE_VP__REGS_APB_ENC1_RC_CONFIG_p
  fields as V2A__CORE_VP__REGS_APB_ENC0_RC_CONFIG_p
0x30E54 V2A__CORE_VP__REGS_APB_ENC1_RC_BUF_THRESH_0_p rw
  fields as V2A__CORE_VP__REGS_APB_ENC0_RC_BUF_THRESH_0_p
0x30E58 V2A__CORE_VP__REGS_APB_ENC1_RC_BUF_THRESH_1_p rw
  fields as V2A__CORE_VP__REGS_APB_ENC0_RC_BUF_THRESH_1_p
0x30E5C V2A__CORE_VP__REGS_APB_ENC1_RC_BUF_THRESH_2_p rw
  fields as V2A__CORE_VP__REGS_APB_ENC0_RC_BUF_THRESH_2_p
0x30E60 V2A__CORE_VP__REGS_APB_ENC1_RC_BUF_THRESH_3_p
  [31:16] RESERVED — 8 MSBs of the value. Values in configuration files are 14 bits but 6 LSBs are always 0 (access N/A)
  [15:8] RC_BUF_THRESH_13 rw — 8 MSBs of the value. Values in configuration files are 14 bits but 6 LSBs are always 0
  [7:0] RC_BUF_THRESH_12 rw — 8 MSBs of the value. Values in configuration files are 14 bits but 6 LSBs are always 0
0x30E64 V2A__CORE_VP__REGS_APB_ENC1_RC_MIN_QP_0_p
  [5n+4:5n] RANGE_MIN_QP_{n} rw (n=0..4) — As per DSC specification
0x30E68 V2A__CORE_VP__REGS_APB_ENC1_RC_MIN_QP_1_p
  fields as V2A__CORE_VP__REGS_APB_ENC0_RC_MIN_QP_1_p
0x30E6C V2A__CORE_VP__REGS_APB_ENC1_RC_MIN_QP_2_p
  fields as V2A__CORE_VP__REGS_APB_ENC0_RC_MIN_QP_2_p
0x30E70 V2A__CORE_VP__REGS_APB_ENC1_RC_MAX_QP_0_p
  [5n+4:5n] RANGE_MAX_QP_{n} rw (n=0..4) — As per DSC specification
0x30E74 V2A__CORE_VP__REGS_APB_ENC1_RC_MAX_QP_1_p
  fields as V2A__CORE_VP__REGS_APB_ENC0_RC_MAX_QP_1_p
0x30E78 V2A__CORE_VP__REGS_APB_ENC1_RC_MAX_QP_2_p
  fields as V2A__CORE_VP__REGS_APB_ENC0_RC_MAX_QP_2_p
0x30E7C V2A__CORE_VP__REGS_APB_ENC1_RC_RANGE_BPG_OFFSETS_0_p
  fields as V2A__CORE_VP__REGS_APB_ENC0_RC_RANGE_BPG_OFFSETS_0_p
0x30E80 V2A__CORE_VP__REGS_APB_ENC1_RC_RANGE_BPG_OFFSETS_1_p
  fields as V2A__CORE_VP__REGS_APB_ENC0_RC_RANGE_BPG_OFFSETS_1_p
0x30E84 V2A__CORE_VP__REGS_APB_ENC1_RC_RANGE_BPG_OFFSETS_2_p
  fields as V2A__CORE_VP__REGS_APB_ENC0_RC_RANGE_BPG_OFFSETS_2_p
0x30E88 V2A__CORE_VP__REGS_APB_ENC1_DPI_CTRL_OUT_DELAY_p
  fields as V2A__CORE_VP__REGS_APB_ENC0_DPI_CTRL_OUT_DELAY_p
0x30EC0 V2A__CORE_VP__REGS_APB_ENC1_GENERAL_STATUS_p reset 0x18
  fields as V2A__CORE_VP__REGS_APB_ENC0_GENERAL_STATUS_p
0x30EC4 V2A__CORE_VP__REGS_APB_ENC1_HSLICE_STATUS_p ro
  fields as V2A__CORE_VP__REGS_APB_ENC0_HSLICE_STATUS_p
0x30EC8 V2A__CORE_VP__REGS_APB_ENC1_OUT_STATUS_p ro
  fields as V2A__CORE_VP__REGS_APB_ENC0_OUT_STATUS_p
0x30ECC V2A__CORE_VP__REGS_APB_ENC1_INT_STAT_p
  [10] OUT_BUFF_FULL_CONTEXT_1 ro — Output buffer 1 [soft slice 1] became full
  [9] OUT_BUFF_FULL_CONTEXT_0 ro — Output buffer 0 [soft slice 0] became full
  [8] OUT_BUFF_EMPTY_CONTEXT_1 ro — Output buffer 1 [soft slice 1] became empty
  [7] OUT_BUFF_EMPTY_CONTEXT_0 ro — Output buffer 0 [soft slice 0] became empty
  [6] FRAME_DONE ro — Encoder finished a frame
  [5] FRAME_STARTED ro — Encoder is started to process a frame
  [4] CE ro — Flow control internal clock enable becomes high
  [3] RC_MODEL_BUFFER_FULLNESS_OVERFLOW_CONTEXT_1 ro — output buffer 1 [soft slice 1] underflow
  [2] RC_MODEL_BUFFER_FULLNESS_OVERFLOW_CONTEXT_0 ro — output buffer 0 [soft slice 0] underflow
  [1] ENC_UNDERFLOW_CONTEXT_1 ro — output buffer 1 [soft slice 1] underflow
  [0] ENC_UNDERFLOW_CONTEXT_0 ro — output buffer 0 [soft slice 0] underflow
0x30ED0 V2A__CORE_VP__REGS_APB_ENC1_INT_CLR_p
  fields as V2A__CORE_VP__REGS_APB_ENC0_INT_CLR_p
0x30ED4 V2A__CORE_VP__REGS_APB_ENC1_INT_MASK_p
  fields as V2A__CORE_VP__REGS_APB_ENC0_INT_MASK_p
0x30ED8 V2A__CORE_VP__REGS_APB_ENC1_INT_TEST_p
  fields as V2A__CORE_VP__REGS_APB_ENC0_INT_TEST_p
0x30F00 V2A__CORE_VP__REGS_APB_ENC_ASF_INT_STAT_p
  [8] ASF_CSR_ERR ro — Configuration and status registers uncorrectable error interrupt
  [7] ENC1_SELF_CHK_ERR ro — Hard Slice 1 Encoder self-check uncorrectable error interrupt
  [6] ENC1_OUT_CHK_ERR ro — Hard Slice 1 Encoder output checker uncorrectable error interrupt
  [5] ENC1_ASF_SRAM_UNCORR_ERR ro — Hard Slice 1 SRAM uncorrectable error interrupt
  [4] ENC1_ASF_SRAM_CORR_ERR ro — Hard Slice 1 SRAM correctable error interrupt
  [3] ENC0_SELF_CHK_ERR ro — Hard Slice 0 Encoder self-check uncorrectable error interrupt
  [2] ENC0_OUT_CHK_ERR ro — Hard Slice 0 Encoder output checker uncorrectable error interrupt
  [1] ENC0_ASF_SRAM_UNCORR_ERR rw — Hard Slice 0 SRAM uncorrectable error interrupt
  [0] ENC0_ASF_SRAM_CORR_ERR ro — Hard Slice 0 SRAM correctable error interrupt
0x30F04 V2A__CORE_VP__REGS_APB_ENC_ASF_INT_MASK_p
  [8] ASF_CSR_ERR rw — Configuration and status registers uncorrectable error interrupt
  [7] ENC1_SELF_CHK_ERR rw — Hard Slice 1 Encoder self-check uncorrectable error interrupt
  [6] ENC1_OUT_CHK_ERR rw — Hard Slice 1 Encoder output checker uncorrectable error interrupt
  [5] ENC1_ASF_SRAM_UNCORR_ERR rw — Hard Slice 1 SRAM uncorrectable error interrupt
  [4] ENC1_ASF_SRAM_CORR_ERR rw — Hard Slice 1 SRAM correctable error interrupt
  [3] ENC0_SELF_CHK_ERR rw — Hard Slice 0 Encoder self-check uncorrectable error interrupt
  [2] ENC0_OUT_CHK_ERR rw — Hard Slice 0 Encoder output checker uncorrectable error interrupt
  [1] ENC0_ASF_SRAM_UNCORR_ERR rw — Hard Slice 0 SRAM uncorrectable error interrupt
  [0] ENC0_ASF_SRAM_CORR_ERR rw — Hard Slice 0 SRAM correctable error interrupt
0x30F08 V2A__CORE_VP__REGS_APB_ENC_ASF_INT_CLR_p
  fields as V2A__CORE_VP__REGS_APB_ENC_ASF_INT_MASK_p
0x30F0C V2A__CORE_VP__REGS_APB_ENC_ASF_INT_TEST_p
  [8] ASF_CSR_ERR rw — Configuration and status registers uncorrectable error interrupt test
  [7] ENC1_SELF_CHK_ERR rw — Hard Slice 1 Encoder self-check uncorrectable error interrupt test
  [6] ENC1_OUT_CHK_ERR rw — Hard Slice 1 Encoder output checker uncorrectable error interrupt test
  [5] ENC1_ASF_SRAM_UNCORR_ERR rw — Hard Slice 1 SRAM uncorrectable error interrupt test
  [4] ENC1_ASF_SRAM_CORR_ERR rw — Hard Slice 1 SRAM correctable error interrupt test
  [3] ENC0_SELF_CHK_ERR rw — Hard Slice 0 Encoder self-check uncorrectable error interrupt test
  [2] ENC0_OUT_CHK_ERR rw — Hard Slice 0 Encoder output checker uncorrectable error interrupt test
  [1] ENC0_ASF_SRAM_UNCORR_ERR rw — Hard Slice 0 SRAM uncorrectable error interrupt test
  [0] ENC0_ASF_SRAM_CORR_ERR rw — Hard Slice 0 SRAM correctable error interrupt test
0x30F20 V2A__CORE_VP__REGS_APB_ENC0_ASF_SRAM_CORR_p
  [25:24] ASF_SRAM_CORR_FAULT_INST ro — Last SRAM instance that generated fault. In case of simultaneous faults, priority is given to the highest number below. 3: SSM_S 2: SSM_D 1: Output Buffer 0: Line Buffer
  [23:0] ASF_SRAM_CORR_FAULT_ADDR ro — Last SRAM address that generated fault
0x30F24 V2A__CORE_VP__REGS_APB_ENC0_ASF_SRAM_UNCORR_p
  [25:24] ASF_SRAM_UNCORR_FAULT_INST ro — Last SRAM instance that generated fault. In case of simultaneous faults, priority is given to the highest number below. 3: SSM_S 2: SSM_D 1: Output Buffer 0: Line Buffer
  [23:0] ASF_SRAM_UNCORR_FAULT_ADDR ro — Last SRAM address that generated fault
0x30F28 V2A__CORE_VP__REGS_APB_ENC1_ASF_SRAM_CORR_p
  fields as V2A__CORE_VP__REGS_APB_ENC0_ASF_SRAM_CORR_p
0x30F2C V2A__CORE_VP__REGS_APB_ENC1_ASF_SRAM_UNCORR_p
  fields as V2A__CORE_VP__REGS_APB_ENC0_ASF_SRAM_UNCORR_p
0x30F30 V2A__CORE_VP__REGS_APB_ENC0_ASF_CSR_CHK_TEST_p
  [15:0] ENC0_ASF_CSR_CHK_TEST rw — Each bit of the expected CRC can be corrupted separately [one bit at a time] using this register.
0x30F34 V2A__CORE_VP__REGS_APB_ENC1_ASF_CSR_CHK_TEST_p
  [15:0] ENC1_ASF_CSR_CHK_TEST rw — Each bit of the expected CRC can be corrupted separately [one bit at a time] using this register.
0x30F38 V2A__CORE_VP__REGS_APB_ENC0_ASF_SELF_CHK_TEST_p
  [15:0] ENC0_ASF_SELF_CHK_TEST rw — Each bit of the expected CRC can be corrupted separately [one bit at a time] using this register.
0x30F3C V2A__CORE_VP__REGS_APB_ENC1_ASF_SELF_CHK_TEST_p
  [15:0] ENC1_ASF_SELF_CHK_TEST rw — Each bit of the expected CRC can be corrupted separately [one bit at a time] using this register.
0x30F40 V2A__CORE_VP__REGS_APB_ENC0_ASF_OUT_CHK_TEST_p
  [8] END_FRAME_OUT_STUCK1_ERR rw, [7] END_LINE_OUT_STUCK1_ERR rw, [6] END_CHUNK_STUCK1_ERR rw, [5] VALID_OUT_STUCK1_ERR rw, [4] DATA_OUT_STUCK1_ERR rw, [3] VALID_STUCK0_ERR rw, [2] NVB_VALUE_ERR rw, [1] LINE_CNT_ERR rw, [0] BYTE_CNT_ERR rw
0x30F44 V2A__CORE_VP__REGS_APB_ENC1_ASF_OUT_CHK_TEST_p
  fields as V2A__CORE_VP__REGS_APB_ENC0_ASF_OUT_CHK_TEST_p
